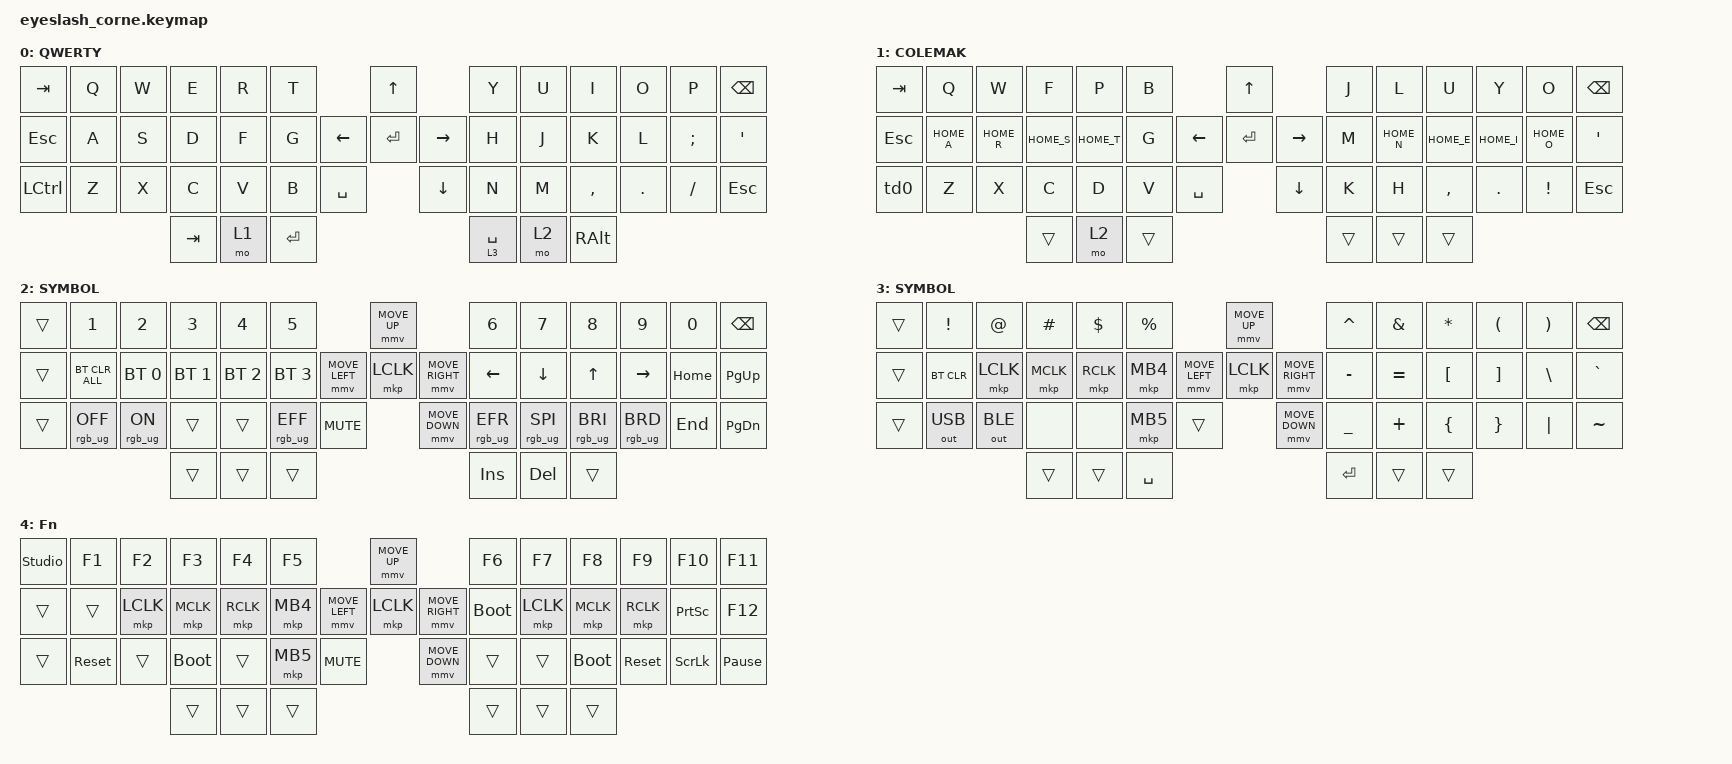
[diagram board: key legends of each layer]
#define ZMK_POINTING_DEFAULT_MOVE_VAL 1200  // 600
#define ZMK_POINTING_DEFAULT_SCRL_VAL 25   // 10

#include <input/processors.dtsi>
#include <zephyr/dt-bindings/input/input-event-codes.h>
#include <behaviors.dtsi>
#include <dt-bindings/zmk/bt.h>
#include <dt-bindings/zmk/ext_power.h>
#include <dt-bindings/zmk/keys.h>
#include <dt-bindings/zmk/pointing.h>
#include <dt-bindings/zmk/outputs.h>
#include <dt-bindings/zmk/rgb.h>

// home row mods for qwerty
#define QH_S LALT S
#define QH_D LSFT D
#define QH_F LGUI F
#define QH_J RGUI J
#define QH_K RSFT K
#define QH_L LALT L
#define QH_SCLN RCTL SCLN

// home row mods COLEMAK
#define HOME_A LCTL A
#define HOME_R LALT R
#define HOME_S LSFT S
#define HOME_T LGUI T
#define HOME_N RGUI N
#define HOME_E RSFT E
#define HOME_I LALT I
#define HOME_O RCTL O

&mmv_input_listener { input-processors = <&zip_xy_scaler 2 1>; };

&msc_input_listener { input-processors = <&zip_scroll_scaler 2 1>; };

&msc {
    acceleration-exponent = <1>;      // 0
    time-to-max-speed-ms = <100>;       // 300
    delay-ms = <0>;                   // 0
};

&mmv {
    time-to-max-speed-ms = <500>;
    acceleration-exponent = <1>;
    trigger-period-ms = <16>;
};


/ {
    behaviors {
        td0: td0 {
            compatible = "zmk,behavior-tap-dance";
            display-name = "Shift/Caps Lock Tap Dance";
            #binding-cells = <0>;
            bindings = <&kp LEFT_SHIFT>, <&kp CAPS>;
        };
    };

    rgb_encoder: rgb_encoder {
        compatible = "zmk,behavior-sensor-rotate";
        #sensor-binding-cells = <0>;
        bindings = <&rgb_ug RGB_BRI>, <&rgb_ug RGB_BRD>;
    };

    scroll_encoder: scroll_encoder {
        compatible = "zmk,behavior-sensor-rotate";
        #sensor-binding-cells = <0>;
        bindings = <&msc SCRL_DOWN>, <&msc SCRL_UP>;
        tap-ms = <100>;
    };

    keymap {
        compatible = "zmk,keymap";

        qwerty_layer {
            display-name = "QWERTY";
            bindings = <
&kp TAB    &kp Q  &kp W      &kp E     &kp R  &kp T                              &kp UP                &kp Y        &kp U  &kp I      &kp O    &kp P     &kp BSPC
&kp ESC    &kp A  &kp S      &kp D     &kp F  &kp G                    &kp LEFT  &kp ENTER  &kp RIGHT  &kp H        &kp J  &kp K      &kp L    &kp SEMI  &kp SQT
&kp LCTRL  &kp Z  &kp X      &kp C     &kp V  &kp B       &kp SPACE              &kp DOWN              &kp N        &kp M  &kp COMMA  &kp DOT  &kp FSLH  &kp ESC
                             &kp TAB   &mo 1  &kp ENTER                                                &lt 3 SPACE  &mo 2  &kp RALT
            >;
            sensor-bindings = <&inc_dec_kp C_VOLUME_UP C_VOLUME_DOWN>;
        };

        default_layer {
            display-name = "COLEMAK";
            bindings = <
&kp TAB    &kp Q    &kp W      &kp F     &kp P   &kp B                              &kp UP                &kp J        &kp L   &kp U      &kp Y    &kp O     &kp BSPC
&kp ESC    HOME_A   HOME_R     HOME_S    HOME_T  &kp G                    &kp LEFT  &kp ENTER  &kp RIGHT  &kp M        HOME_N  HOME_E     HOME_I   HOME_O     &kp SQT
&td0       &kp Z    &kp X      &kp C     &kp D   &kp V       &kp SPACE              &kp DOWN              &kp K        &kp H   &kp COMMA  &kp DOT  &kp EXCL  &kp ESC
                             &trans    &mo 2  &trans                                                   &trans       &trans &trans
            >;
            sensor-bindings = <&inc_dec_kp C_VOLUME_UP C_VOLUME_DOWN>;
        };

        sym_layer {
            display-name = "SYMBOL";
            bindings = <
&trans  &kp N1           &kp N2          &kp N3        &kp N4        &kp N5                                        &mmv MOVE_UP                     &kp N6           &kp N7           &kp N8           &kp N9           &kp N0    &kp BSPC
&trans  &bt BT_CLR_ALL   &bt BT_SEL 0    &bt BT_SEL 1  &bt BT_SEL 2  &bt BT_SEL 3                           &mmv MOVE_LEFT  &mkp LCLK       &mmv MOVE_RIGHT  &kp LEFT         &kp DOWN         &kp UP           &kp RIGHT        &kp HOME  &kp PG_UP
&trans  &rgb_ug RGB_OFF  &rgb_ug RGB_ON  &trans        &trans        &rgb_ug RGB_EFF &kp C_MUTE                    &mmv MOVE_DOWN                   &rgb_ug RGB_EFR  &rgb_ug RGB_SPI  &rgb_ug RGB_BRI  &rgb_ug RGB_BRD  &kp END   &kp PG_DN
                                         &trans        &trans        &trans                                                                         &kp INS          &kp DEL          &trans
            >;
            sensor-bindings = <&rgb_encoder>;
        };

        raise_layer {
            display-name = "SYMBOL";
            bindings = <
&trans  &kp EXCL      &kp AT        &kp HASH   &kp DLLR   &kp PRCNT                           &mmv MOVE_UP                     &kp CARET  &kp AMPS   &kp ASTRK  &kp LPAR  &kp RPAR  &kp BSPC
&trans  &bt BT_CLR    &mkp LCLK     &mkp MCLK  &mkp RCLK  &mkp MB4            &mmv MOVE_LEFT  &mkp LCLK       &mmv MOVE_RIGHT  &kp MINUS  &kp EQUAL  &kp LBKT   &kp RBKT  &kp BSLH  &kp GRAVE
&trans  &out OUT_USB  &out OUT_BLE  &none      &none      &mkp MB5  &trans                    &mmv MOVE_DOWN                   &kp UNDER  &kp PLUS   &kp LBRC   &kp RBRC  &kp PIPE  &kp TILDE
                                    &trans     &trans     &kp SPACE                                                            &kp RET    &trans     &trans
            >;
            sensor-bindings = <&scroll_encoder>;
        };

        layer_3 {
            display-name = "Fn";
            bindings = <
&studio_unlock   &kp F1      &kp F2      &kp F3       &kp F4     &kp F5                                  &mmv MOVE_UP                     &kp F6       &kp F7     &kp F8       &kp F9      &kp F10          &kp F11
&trans  &trans      &mkp LCLK   &mkp MCLK    &mkp RCLK  &mkp MB4                &mmv MOVE_LEFT  &mkp LCLK       &mmv MOVE_RIGHT  &bootloader  &mkp LCLK  &mkp MCLK    &mkp RCLK   &kp PRINTSCREEN  &kp F12
&trans  &sys_reset  &trans      &bootloader  &trans     &mkp MB5  &kp C_MUTE                    &mmv MOVE_DOWN                   &trans       &trans     &bootloader  &sys_reset  &kp SCROLLLOCK   &kp PAUSE_BREAK
                                &trans      &trans      &trans                                                                   &trans       &trans     &trans
            >;
            sensor-bindings = <&scroll_encoder>;
        };
    };
};
